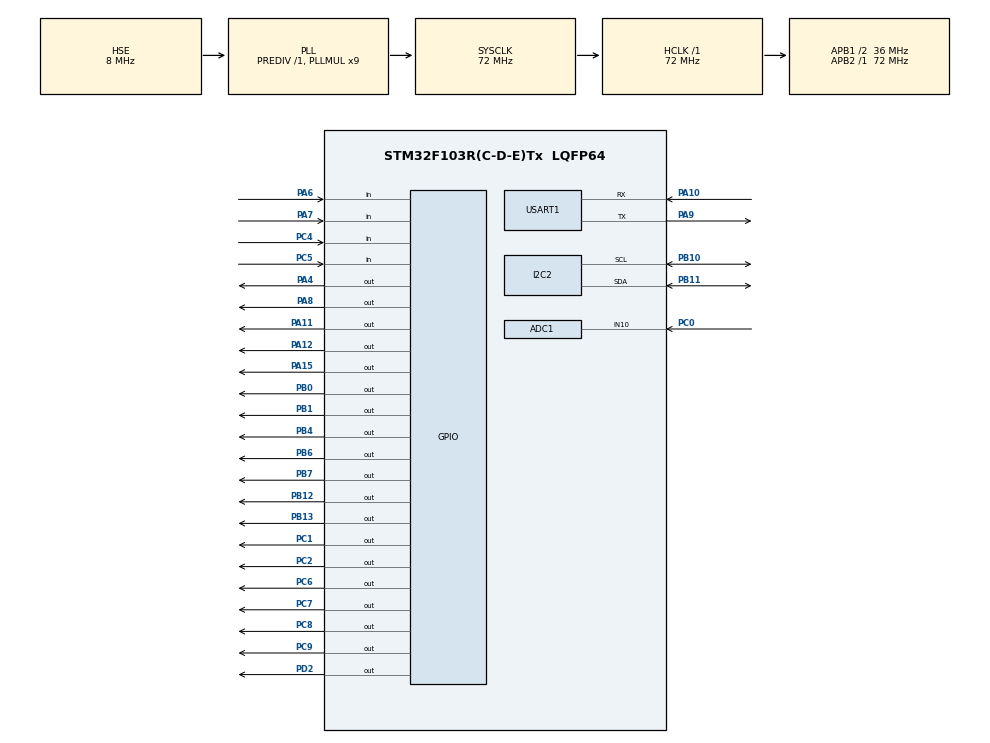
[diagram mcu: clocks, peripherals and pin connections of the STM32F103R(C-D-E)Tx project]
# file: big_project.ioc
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ADC1.Channel-3\#ChannelRegularConversion=ADC_CHANNEL_10
ADC1.ContinuousConvMode=ENABLE
ADC1.NbrOfConversionFlag=1
ADC1.Rank-3\#ChannelRegularConversion=1
ADC1.SamplingTime-3\#ChannelRegularConversion=ADC_SAMPLETIME_1CYCLE_5
ADC1.master=1
Mcu.Family=STM32F1
Mcu.Name=STM32F103R(C-D-E)Tx
Mcu.Package=LQFP64
NVIC.PriorityGroup=NVIC_PRIORITYGROUP_4
NVIC.TIM2_IRQn=true\:0\:0\:false\:false\:true\:true
NVIC.USART1_IRQn=true\:0\:0\:false\:false\:true\:true
PA10.Mode=Asynchronous
PA10.Signal=USART1_RX
PA11.Signal=GPIO_Output
PA12.Signal=GPIO_Output
PA15.Signal=GPIO_Output
PA4.Signal=GPIO_Output
PA6.Signal=GPIO_Input
PA7.Signal=GPIO_Input
PA8.Signal=GPIO_Output
PA9.Mode=Asynchronous
PA9.Signal=USART1_TX
PB0.Signal=GPIO_Output
PB1.Signal=GPIO_Output
PB10.Mode=I2C
PB10.Signal=I2C2_SCL
PB11.Mode=I2C
PB11.Signal=I2C2_SDA
PB12.Signal=GPIO_Output
PB13.Signal=GPIO_Output
PB4.Signal=GPIO_Output
PB6.Signal=GPIO_Output
PB7.Signal=GPIO_Output
PC0.Signal=ADCx_IN10
PC1.Signal=GPIO_Output
PC2.Signal=GPIO_Output
PC4.Signal=GPIO_Input
PC5.Signal=GPIO_Input
PC6.Signal=GPIO_Output
PC7.Signal=GPIO_Output
PC8.Signal=GPIO_Output
PC9.Signal=GPIO_Output
PD0-OSC_IN.Mode=HSE-External-Oscillator
PD0-OSC_IN.Signal=RCC_OSC_IN
PD1-OSC_OUT.Mode=HSE-External-Oscillator
PD1-OSC_OUT.Signal=RCC_OSC_OUT
PD2.Signal=GPIO_Output
ProjectManager.HeapSize=0x200
ProjectManager.StackSize=0x400
ProjectManager.TargetToolchain=MDK-ARM V5
RCC.ADCPresc=RCC_ADCPCLK2_DIV6
RCC.AHBFreq_Value=72000000
RCC.APB1CLKDivider=RCC_HCLK_DIV2
RCC.APB1Freq_Value=36000000
RCC.APB1TimFreq_Value=72000000
RCC.APB2Freq_Value=72000000
RCC.APB2TimFreq_Value=72000000
RCC.HCLKFreq_Value=72000000
RCC.PLLMUL=RCC_PLL_MUL9
RCC.PLLSourceVirtual=RCC_PLLSOURCE_HSE
RCC.SYSCLKFreq_VALUE=72000000
RCC.SYSCLKSource=RCC_SYSCLKSOURCE_PLLCLK
RCC.USBFreq_Value=72000000
SH.ADCx_IN10.0=ADC1_IN10,IN10
TIM2.AutoReloadPreload=TIM_AUTORELOAD_PRELOAD_ENABLE
TIM2.Period=10000
TIM2.Prescaler=7199
USART1.VirtualMode=VM_ASYNC
VP_SYS_VS_ND.Mode=No_Debug
VP_TIM2_VS_ClockSourceINT.Mode=Internal
board=custom

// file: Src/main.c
/* USER CODE BEGIN Header */
/**
  ******************************************************************************
  * @file           : main.c
  * @brief          : Main program body
  ******************************************************************************
  ** This notice applies to any and all portions of this file
  * that are not between comment pairs USER CODE BEGIN and
  * USER CODE END. Other portions of this file, whether
  * inserted by the user or by software development tools
  * are owned by their respective copyright owners.
  *
  * COPYRIGHT(c) 2019 STMicroelectronics
  *
  * Redistribution and use in source and binary forms, with or without modification,
  * are permitted provided that the following conditions are met:
  *   1. Redistributions of source code must retain the above copyright notice,
  *      this list of conditions and the following disclaimer.
  *   2. Redistributions in binary form must reproduce the above copyright notice,
  *      this list of conditions and the following disclaimer in the documentation
  *      and/or other materials provided with the distribution.
  *   3. Neither the name of STMicroelectronics nor the names of its contributors
  *      may be used to endorse or promote products derived from this software
  *      without specific prior written permission.
  *
  * THIS SOFTWARE IS PROVIDED BY THE COPYRIGHT HOLDERS AND CONTRIBUTORS "AS IS"
  * AND ANY EXPRESS OR IMPLIED WARRANTIES, INCLUDING, BUT NOT LIMITED TO, THE
  * IMPLIED WARRANTIES OF MERCHANTABILITY AND FITNESS FOR A PARTICULAR PURPOSE ARE
  * DISCLAIMED. IN NO EVENT SHALL THE COPYRIGHT HOLDER OR CONTRIBUTORS BE LIABLE
  * FOR ANY DIRECT, INDIRECT, INCIDENTAL, SPECIAL, EXEMPLARY, OR CONSEQUENTIAL
  * DAMAGES (INCLUDING, BUT NOT LIMITED TO, PROCUREMENT OF SUBSTITUTE GOODS OR
  * SERVICES; LOSS OF USE, DATA, OR PROFITS; OR BUSINESS INTERRUPTION) HOWEVER
  * CAUSED AND ON ANY THEORY OF LIABILITY, WHETHER IN CONTRACT, STRICT LIABILITY,
  * OR TORT (INCLUDING NEGLIGENCE OR OTHERWISE) ARISING IN ANY WAY OUT OF THE USE
  * OF THIS SOFTWARE, EVEN IF ADVISED OF THE POSSIBILITY OF SUCH DAMAGE.
  *
  ******************************************************************************
  */
/* USER CODE END Header */

#include "main.h"

/* USER CODE BEGIN Includes */
#include "string.h"
#include "math.h"
/* USER CODE END Includes */

ADC_HandleTypeDef hadc1;

I2C_HandleTypeDef hi2c2;

TIM_HandleTypeDef htim2;

UART_HandleTypeDef huart1;

/* USER CODE BEGIN PV */
void key_handle(int key);
/* USER CODE END PV */

void SystemClock_Config(void);
static void MX_GPIO_Init(void);
static void MX_USART1_UART_Init(void);
static void MX_TIM2_Init(void);
static void MX_I2C2_Init(void);
static void MX_ADC1_Init(void);

/* USER CODE BEGIN 0 */
int Tick_ms = 0;
int temp_test2 = 0;
 //设置温度 报警的上下限

int set_para2[4]= {60,20,80,10};
int set_para[4] = {60,20,80,10};  //里面分别是 温度上限，温度下限，报警上限，报警下限。
int get_key[4]={0,0,0,0}; // 用来放按下的有效键
int value_key[] = {12,13,14,15};// 设置键为 温度上限，温度下限 报警上限 报警下限
int delay_time10s=0; // 超过10s没有按键 默认取消操作
int setting = 0;  // 判断是否在设置
int view_para = 0; // 查看参数
struct GPIO_PACK{
		GPIO_TypeDef * port;
		uint16_t pin;
	};
	struct GPIO_PACK segs[8]= {
	{GPIOA,GPIO_PIN_15},
	{GPIOA,GPIO_PIN_11},
	{GPIOC,GPIO_PIN_9},
	{GPIOC,GPIO_PIN_7},
	{GPIOC,GPIO_PIN_8},
	{GPIOA,GPIO_PIN_12},
	{GPIOA,GPIO_PIN_8},
	{GPIOC,GPIO_PIN_6},
	}	;
	struct GPIO_PACK bits[4]={
	{GPIOD,GPIO_PIN_2},
	{GPIOB,GPIO_PIN_4},
	{GPIOB,GPIO_PIN_6},
	{GPIOB,GPIO_PIN_7},

	};
	struct GPIO_PACK led_array[8]=
{
	{GPIOA,GPIO_PIN_4},
	{GPIOA,GPIO_PIN_3},
	{GPIOA,GPIO_PIN_2},
	{GPIOA,GPIO_PIN_1},
	{GPIOA,GPIO_PIN_0},
	{GPIOC,GPIO_PIN_3},
	{GPIOC,GPIO_PIN_2},
	{GPIOC,GPIO_PIN_1},
};
uint8_t shuzu[]={
	0xc0,0xf9,0xa4,0xb0,0x99,0x92,0x82,
	0xf8,0x80,0x90,0xbf
};
uint8_t shuzu2[] = {
	0x40,0x79,0x24,0x30,0x19,0x12,0x2,
	0x78,0x0,0x10
};
void delay1ms (unsigned int a){ // 1ms????(12MHz 10??51??????)
	unsigned int i;
	while( a-- != 0){
		for(i = 0; i < 600; i++);
	}
}
void DisplayOnebit(uint8_t digtal,uint8_t bit){
		uint8_t i;
		for(i=0;i<8;i++){
			HAL_GPIO_WritePin(segs[i].port,segs[i].pin,(GPIO_PinState)(shuzu[digtal]&(0x01<<i)));
		}
		for(i=0;i<4;i++){
			HAL_GPIO_WritePin(bits[i].port,bits[i].pin,(GPIO_PinState)(i!=bit));
		}
		delay1ms(6);
}
void DisplayOnebit2(uint8_t digtal,uint8_t bit){
		uint8_t i;
		for(i=0;i<8;i++){
			HAL_GPIO_WritePin(segs[i].port,segs[i].pin,(GPIO_PinState)(shuzu2[digtal]&(0x01<<i)));
		}
		for(i=0;i<4;i++){
			HAL_GPIO_WritePin(bits[i].port,bits[i].pin,(GPIO_PinState)(i!=bit));
		}
		//HAL_Delay(2);
		delay1ms(6);
}

void DisplayDigtal(uint16_t digtal){

	DisplayOnebit(digtal%10,0);
	HAL_Delay(5);
	if (digtal>=10){
	DisplayOnebit(digtal/10%10,1);
	HAL_Delay(5);
	if (digtal>=100){
	DisplayOnebit(digtal/100%10,2);
	HAL_Delay(5);
	if (digtal>=1000){
	DisplayOnebit(digtal/1000%10,3);
	HAL_Delay(5);

				}
			}
		}
}
struct GPIO_PACK lie[4]={
   {GPIOB,GPIO_PIN_0},
   {GPIOB,GPIO_PIN_1},
   {GPIOB,GPIO_PIN_13},
   {GPIOB,GPIO_PIN_12}
};
struct GPIO_PACK hang[4]={
   {GPIOA,GPIO_PIN_6},
   {GPIOA,GPIO_PIN_7},
   {GPIOC,GPIO_PIN_4},
   {GPIOC,GPIO_PIN_5}
};
void Displaykeying()
	{
		uint8_t i,j,s;uint8_t k=1;volatile int key =0;
		for(i=0;i<4;i++)
	{	 HAL_GPIO_WritePin(lie[i].port,lie[i].pin,GPIO_PIN_RESET);
		for(s=0;s<4;s++){
		if(i!=s)
			HAL_GPIO_WritePin(lie[s].port,lie[s].pin,GPIO_PIN_SET);}
		for(j=0;j<4;j++)
	{	k=HAL_GPIO_ReadPin(hang[j].port,hang[j].pin);
		if(k==0)
			HAL_Delay(5);
			if(k==0)
			switch(j)
			{
				case 0:key=j+1+i;break;
				case 1:key=j+4+i;break;
				case 2:key=j+7+i;break;
				case 3:key=j+10+i;break;
			}
		}
	}
	if (key!=0)
		key_handle(key);
	else
		view_para = 0;
}
void key_handle(int key)  // 此处需要进行对 key 进行判断并做相应的处理
{
for(int j =0;j<4;j++)
	{
		if (value_key[j]==key)
		{
		get_key[0]=key;
		delay_time10s=0;
			setting = 1;
		}
	}
	if(get_key[0]!=0 & key == 11) // 设置负数
	{
		delay_time10s=0;
		setting = 1;
		get_key[1]=1;
	}
	if (get_key[0]!=0 & key<=10 & key!=0)
	{

		int key_time_delay = delay_time10s;
		delay_time10s=0;  // 重新计时  10s
		setting = 1;
	 if (get_key[2]!=0)
	 {
		if(key_time_delay<=2 & key==get_key[2]) //由于有按键抖动，按一下可能获取到了多个值，用delay可能会解决不掉
																						//判断上一次和这次的输入时间差  如果小于2秒而且两次的值一样 就认为是抖动造成的
		get_key[3] = 0;
		else
			get_key[3] = key;
	 }else if(get_key[2]==0)
	 {
	 get_key[2] = key;
	 }

	}

	if(get_key[0]!=0 & get_key[2]!=0 & key==16)  //确认保存键
	{

		handle_get_key(get_key);
		setpara_towrite();
		for (int i =0;i<4;i++)
				get_key [i]= 0;
		setting = 0;

	}
	if(get_key[0]==0 & key == 16) // 查看报警上下限
	{
		view_para=1;
	}else
	view_para = 0;

}

#define ADDR_AT24C02_Write 0xA0
#define ADDR_AT24C02_Read 0xA1
#define BufferSize 0x100
uint16_t i;
uint8_t  AT24c02_flag;//
uint8_t params[12]="0";  //用来写入和读出
uint8_t trans_str[2]="0";  // 用来把整形转换为字符型
//int set_para[4] = {60,20,80,10};  //里面分别是 温度上限，温度下限，报警上限，报警下限。
//int value_key[] = {12,13,14,15};// 设置键为 温度上限，温度下限 报警上限 报警下限

void Int2Str(uint8_t* str, int intnum)   //将无符号整形整数intnum 转换成字符 str
{
    int i, Div = 1000000000, j = 0, Status = 0;
    for (i = 0; i < 10; i++)
    {
        str[j++] = (intnum / Div) + '0';
        intnum = intnum % Div;//?????
        Div /= 10;
        if ((str[j-1] == '0') & (Status == 0))
            j = 0;
        else
            Status++;
    }
}
void handle_get_key(int *handle_key)  // 当有值被改变后 对参数进行修改
{
	int set_value;
	if (handle_key[3] ==0 ) // 只输入了一位数
		set_value =handle_key[2];
	else
		set_value = handle_key[2]*10+handle_key[3]%10; // 10代表的是0 而且 所以用了取余省去了很多的判断
	if (handle_key[1]==1)
		set_value = ~set_value+1; // 取 相反数
	for(int j=0;j<4;j++)  //匹配是哪个功能
	{
 if (handle_key[0]== value_key[j])
	set_para[j]=set_value;
}

}
void warning(int temp_warn)
{
if (temp_warn<=set_para[3]) // 温度低于警报下限
{
HAL_GPIO_WritePin(GPIOC,GPIO_PIN_12,1); //响铃式报警
HAL_GPIO_WritePin(GPIOC,GPIO_PIN_1,1);
delay1ms(2);

}
else if(temp_warn>=set_para[2])//温度高于警报上限
{
HAL_GPIO_WritePin(GPIOC,GPIO_PIN_12,1); //响铃式报警
HAL_GPIO_WritePin(GPIOC,GPIO_PIN_1,1);
delay1ms(3);

}
else
{
	HAL_GPIO_WritePin(GPIOC,GPIO_PIN_1,0);
	HAL_GPIO_WritePin(GPIOC,GPIO_PIN_12,0);
}
}

void setpara_towrite() // 把参数写入 由于需要判断正负数 所以在 数前面添加0或者1来区分

{

//	uint8_t params3[12]="060020080010"; 60 20 80 10 四个数都是整数前面都加0 连在一块写入
//	uint8_t params2[4]="0010";
		//HAL_UART_Transmit_IT(&huart1,paramss,12);
	uint8_t params3[12]="";
	uint8_t params2[4]="";
	int value =0;
 for (int i=0;i<4;i++)
	{

		if (set_para[i]>=0)
		{	strncat(params3,"0",1);
			value = set_para[i];
		}
		else
		{strncat(params3,"1",1);
			value = ~set_para[i]+1;
		}
		Int2Str(trans_str,value);

		if(value>=0 & value<10)
		{	strncat(params3,"0",1);
			strncat(params3,trans_str,1);
		}else
		strncat(params3,trans_str,2);

	}
	for(int j=8;j<12;j++)
{

	params2[j-8]=params3[j];

}

	HAL_I2C_Mem_Write(&hi2c2, ADDR_AT24C02_Write, 0, I2C_MEMADD_SIZE_8BIT,params3,8, 10000);
	HAL_Delay(5);
	HAL_I2C_Mem_Write(&hi2c2, ADDR_AT24C02_Write, 8, I2C_MEMADD_SIZE_8BIT,params2,8, 10000);
	HAL_Delay(5);

}
void handle_readpara()  // 从EEprom中读出来的值进行处理 判断正负以及分开
{
	int num =0;
	int abc ;
for(int i=0;i<12;i++)
	{
		if((i+1)%3 == 1)
		{
			num = (params[i+1]-48)*10+params[i+2]-48;
			abc = params[i]-48;
			if (abc==1)
				num = ~num+1;  // 为1 可以判断为负数
			set_para[i/3]=num;

		}

	}
}
void Display_tube(int temp_test)  // 控制数码管的显示
{
 int ture_num ;
if (view_para!=1)
	{
		if(setting == 0 )
	{
		if(temp_test<0)
			ture_num = ~temp_test+1;
		else
			ture_num = temp_test;

	DisplayOnebit(ture_num%10,0);
	DisplayOnebit2(ture_num/10%10,1);
	if(temp_test>=100)
	{
		DisplayOnebit(ture_num/100,2);
		if(temp_test<0)
		DisplayOnebit(10,3);
		}else if(temp_test<0)
		DisplayOnebit(10,2);  //负数显示一个横杠
	}
	if(setting == 1)
	{
	DisplayOnebit(get_key[0]%10,3);
	DisplayOnebit(9-delay_time10s,2);
	DisplayOnebit(get_key[2]%10,1);
	DisplayOnebit(get_key[3]%10,0);
	}
	}else if(view_para==1) //查看上下限参数
		{
		if (set_para[2]<0)
		{DisplayOnebit2((~set_para[2]+1)%10,2);
			DisplayOnebit((~set_para[2]+1)/10,3);}
			else
			{DisplayOnebit(set_para[2]%10,2);
				DisplayOnebit(set_para[2]/10,3);}
			// 上面是显示上限 下面是下限
			if (set_para[3]<0)
				{DisplayOnebit2((~set_para[3]+1)%10,0);
			DisplayOnebit((~set_para[3]+1)/10,1);}
			else
			{DisplayOnebit(set_para[3]%10,0);
				DisplayOnebit(set_para[3]/10,1);}
		}

}

float array_Temp[] = {  //使用查表法  温度表
-40,-30,-20,-10,-5,-3,-1,0,
2,4,6,8,10,13,15,18,
20,22,24,25,26,27,28,29,
30,31,32,33,34,35,36,37,38,
39,40,42,45,48,52,60,65,
70,75,80,85,90,95,100,105,

};
float array_Resis[] = {   //使用查表法  阻值表
201,116,70.03,43.35,34.48,31.52,28.85,27.62,
25.32,23.23,21.34,19.63,18.07,15.98,14.47,13.09,
12.11,11.21,10.39,10.00,9.631,9.277,8.938,8.613,
8.302,8.004,7.718,7.444,7.180,6.928,6.683,6.654,6.230,
6.016,5.810,5.423,4.897,4.429,3.883,3.001,2.582,
2.223,1.921,1.667,1.451,1.268,1.112,0.977,0,8262,

};
float search_temp(float rsis)  //二分查找法
{
int start=0,end=sizeof(array_Temp);
	int j;
while(1)
{
j = (end + start)/2;
if (rsis > array_Resis[j])
{

	end = j-1;
}
else if (rsis == array_Resis[j])
	break;
else
	start = j+1;
if (end - start <0)
	break;
}

 if (start-end ==1)
{
	float R = (array_Temp[start]-array_Temp[end])/(array_Resis[start]-array_Resis[end])*(rsis-array_Resis[end])+array_Temp[end];
	//DisplayDigtal(end);
	return R;
}else
	return array_Temp[j];

}
float ADC1temp(void)  // AD采样值 计算阻值 并获取温度
{
	 uint16_t ADC1_Value;
  	 float  Rt,t;
	float false_temp,ture_temp;
	 HAL_ADC_Start(&hadc1);
   	HAL_ADC_PollForConversion(&hadc1, 50);
 	if(HAL_IS_BIT_SET(HAL_ADC_GetState(&hadc1), HAL_ADC_STATE_REG_EOC))
  	 {
	   ADC1_Value = HAL_ADC_GetValue(&hadc1);
   	 Rt=(10000*ADC1_Value)/ (4096-ADC1_Value); // 热敏电阻值
			t=(1/(log((Rt/10000))/3380+1/(273.15+25))-273.15);  //t=1/(ln(Rt/R0)/B+1/T0)-273.15
		ture_temp = t*10; // 计算出来的
		false_temp = ((search_temp(Rt))*10);//使用查表法的温度值

		return ture_temp;
 	 }
 }

/* USER CODE END 0 */

int main(void)
{

  /* MCU Configuration--------------------------------------------------------*/

  /* Reset of all peripherals, Initializes the Flash interface and the Systick. */
  HAL_Init();

  /* USER CODE BEGIN Init */
	// HAL_GPIO_TogglePin(GPIOA,GPIO_PIN_1);
//	HAL_GPIO_TogglePin(GPIOA,GPIO_PIN_2);
  /* USER CODE END Init */

  /* Configure the system clock */
  SystemClock_Config();

  /* Initialize all configured peripherals */
  MX_GPIO_Init();
  MX_USART1_UART_Init();
  MX_TIM2_Init();
  MX_I2C2_Init();
  MX_ADC1_Init();
  /* USER CODE BEGIN 2 */

	//HAL_TIM_Base_Start_IT(&htim2); // 开启定时器2的中断

	if(HAL_I2C_Mem_Read(&hi2c2, ADDR_AT24C02_Read,0,I2C_MEMADD_SIZE_8BIT,params,12,1000) == HAL_OK)
	{

		HAL_UART_Transmit_IT(&huart1,params,12);
		handle_readpara(); //处理读出的数值
	}
	int get_temp =ADC1temp();;

  /* USER CODE END 2 */

  /* Infinite loop */
  while (1)
  {

    /* USER CODE BEGIN 3 */
		//Displaykeying();
		if(temp_test2==0)
			get_temp = ADC1temp();// 定时 获取阻值
		warning(get_temp/10); // 对放入的值 判断警报
		Displaykeying();
		Display_tube(get_temp); // 放入的是 get——temp的时候是 温度 放入temp——test2 测试是用来测试

  }

  /* USER CODE END 3 */
}

void SystemClock_Config(void)
{
  RCC_OscInitTypeDef RCC_OscInitStruct = {0};
  RCC_ClkInitTypeDef RCC_ClkInitStruct = {0};
  RCC_PeriphCLKInitTypeDef PeriphClkInit = {0};

  /**Initializes the CPU, AHB and APB busses clocks
  */
  RCC_OscInitStruct.OscillatorType = RCC_OSCILLATORTYPE_HSE;
  RCC_OscInitStruct.HSEState = RCC_HSE_ON;
  RCC_OscInitStruct.HSEPredivValue = RCC_HSE_PREDIV_DIV1;
  RCC_OscInitStruct.HSIState = RCC_HSI_ON;
  RCC_OscInitStruct.PLL.PLLState = RCC_PLL_ON;
  RCC_OscInitStruct.PLL.PLLSource = RCC_PLLSOURCE_HSE;
  RCC_OscInitStruct.PLL.PLLMUL = RCC_PLL_MUL9;
  if (HAL_RCC_OscConfig(&RCC_OscInitStruct) != HAL_OK)
  {
    Error_Handler();
  }
  /**Initializes the CPU, AHB and APB busses clocks
  */
  RCC_ClkInitStruct.ClockType = RCC_CLOCKTYPE_HCLK|RCC_CLOCKTYPE_SYSCLK
                              |RCC_CLOCKTYPE_PCLK1|RCC_CLOCKTYPE_PCLK2;
  RCC_ClkInitStruct.SYSCLKSource = RCC_SYSCLKSOURCE_PLLCLK;
  RCC_ClkInitStruct.AHBCLKDivider = RCC_SYSCLK_DIV1;
  RCC_ClkInitStruct.APB1CLKDivider = RCC_HCLK_DIV2;
  RCC_ClkInitStruct.APB2CLKDivider = RCC_HCLK_DIV1;

  if (HAL_RCC_ClockConfig(&RCC_ClkInitStruct, FLASH_LATENCY_2) != HAL_OK)
  {
    Error_Handler();
  }
  PeriphClkInit.PeriphClockSelection = RCC_PERIPHCLK_ADC;
  PeriphClkInit.AdcClockSelection = RCC_ADCPCLK2_DIV6;
  if (HAL_RCCEx_PeriphCLKConfig(&PeriphClkInit) != HAL_OK)
  {
    Error_Handler();
  }
}

static void MX_ADC1_Init(void)
{

  ADC_ChannelConfTypeDef sConfig = {0};

  /**Common config
  */
  hadc1.Instance = ADC1;
  hadc1.Init.ScanConvMode = ADC_SCAN_DISABLE;
  hadc1.Init.ContinuousConvMode = ENABLE;
  hadc1.Init.DiscontinuousConvMode = DISABLE;
  hadc1.Init.ExternalTrigConv = ADC_SOFTWARE_START;
  hadc1.Init.DataAlign = ADC_DATAALIGN_RIGHT;
  hadc1.Init.NbrOfConversion = 1;
  if (HAL_ADC_Init(&hadc1) != HAL_OK)
  {
    Error_Handler();
  }
  /**Configure Regular Channel
  */
  sConfig.Channel = ADC_CHANNEL_10;
  sConfig.Rank = ADC_REGULAR_RANK_1;
  sConfig.SamplingTime = ADC_SAMPLETIME_1CYCLE_5;
  if (HAL_ADC_ConfigChannel(&hadc1, &sConfig) != HAL_OK)
  {
    Error_Handler();
  }

}

static void MX_I2C2_Init(void)
{

  hi2c2.Instance = I2C2;
  hi2c2.Init.ClockSpeed = 100000;
  hi2c2.Init.DutyCycle = I2C_DUTYCYCLE_2;
  hi2c2.Init.OwnAddress1 = 0;
  hi2c2.Init.AddressingMode = I2C_ADDRESSINGMODE_7BIT;
  hi2c2.Init.DualAddressMode = I2C_DUALADDRESS_DISABLE;
  hi2c2.Init.OwnAddress2 = 0;
  hi2c2.Init.GeneralCallMode = I2C_GENERALCALL_DISABLE;
  hi2c2.Init.NoStretchMode = I2C_NOSTRETCH_DISABLE;
  if (HAL_I2C_Init(&hi2c2) != HAL_OK)
  {
    Error_Handler();
  }

}

static void MX_TIM2_Init(void)
{

  TIM_ClockConfigTypeDef sClockSourceConfig = {0};
  TIM_MasterConfigTypeDef sMasterConfig = {0};

  htim2.Instance = TIM2;
  htim2.Init.Prescaler = 7199;
  htim2.Init.CounterMode = TIM_COUNTERMODE_UP;
  htim2.Init.Period = 10000;
  htim2.Init.ClockDivision = TIM_CLOCKDIVISION_DIV1;
  htim2.Init.AutoReloadPreload = TIM_AUTORELOAD_PRELOAD_ENABLE;
  if (HAL_TIM_Base_Init(&htim2) != HAL_OK)
  {
    Error_Handler();
  }
  sClockSourceConfig.ClockSource = TIM_CLOCKSOURCE_INTERNAL;
  if (HAL_TIM_ConfigClockSource(&htim2, &sClockSourceConfig) != HAL_OK)
  {
    Error_Handler();
  }
  sMasterConfig.MasterOutputTrigger = TIM_TRGO_RESET;
  sMasterConfig.MasterSlaveMode = TIM_MASTERSLAVEMODE_DISABLE;
  if (HAL_TIMEx_MasterConfigSynchronization(&htim2, &sMasterConfig) != HAL_OK)
  {
    Error_Handler();
  }

}

static void MX_USART1_UART_Init(void)
{

  huart1.Instance = USART1;
  huart1.Init.BaudRate = 115200;
  huart1.Init.WordLength = UART_WORDLENGTH_8B;
  huart1.Init.StopBits = UART_STOPBITS_1;
  huart1.Init.Parity = UART_PARITY_NONE;
  huart1.Init.Mode = UART_MODE_TX_RX;
  huart1.Init.HwFlowCtl = UART_HWCONTROL_NONE;
  huart1.Init.OverSampling = UART_OVERSAMPLING_16;
  if (HAL_UART_Init(&huart1) != HAL_OK)
  {
    Error_Handler();
  }

}

static void MX_GPIO_Init(void)
{
  GPIO_InitTypeDef GPIO_InitStruct = {0};

  /* GPIO Ports Clock Enable */
  __HAL_RCC_GPIOD_CLK_ENABLE();
  __HAL_RCC_GPIOC_CLK_ENABLE();
  __HAL_RCC_GPIOA_CLK_ENABLE();
  __HAL_RCC_GPIOB_CLK_ENABLE();

  /*Configure GPIO pin Output Level */
  HAL_GPIO_WritePin(GPIOC, GPIO_PIN_1|GPIO_PIN_12|GPIO_PIN_6|GPIO_PIN_7
                          |GPIO_PIN_8|GPIO_PIN_9, GPIO_PIN_RESET);

  /*Configure GPIO pin Output Level */
  HAL_GPIO_WritePin(GPIOA, GPIO_PIN_4|GPIO_PIN_8|GPIO_PIN_11|GPIO_PIN_12
                          |GPIO_PIN_15, GPIO_PIN_RESET);

  /*Configure GPIO pin Output Level */
  HAL_GPIO_WritePin(GPIOB, GPIO_PIN_0|GPIO_PIN_1|GPIO_PIN_12|GPIO_PIN_13
                          |GPIO_PIN_4|GPIO_PIN_6|GPIO_PIN_7, GPIO_PIN_RESET);

  /*Configure GPIO pin Output Level */
  HAL_GPIO_WritePin(GPIOD, GPIO_PIN_2, GPIO_PIN_RESET);

  /*Configure GPIO pins : PC1 PC2 PC6 PC7
                           PC8 PC9 */
  GPIO_InitStruct.Pin = GPIO_PIN_1|GPIO_PIN_12|GPIO_PIN_6|GPIO_PIN_7
                          |GPIO_PIN_8|GPIO_PIN_9;
  GPIO_InitStruct.Mode = GPIO_MODE_OUTPUT_PP;
  GPIO_InitStruct.Pull = GPIO_NOPULL;
  GPIO_InitStruct.Speed = GPIO_SPEED_FREQ_LOW;
  HAL_GPIO_Init(GPIOC, &GPIO_InitStruct);

  /*Configure GPIO pins : PA4 PA8 PA11 PA12
                           PA15 */
  GPIO_InitStruct.Pin = GPIO_PIN_4|GPIO_PIN_8|GPIO_PIN_11|GPIO_PIN_12
                          |GPIO_PIN_15;
  GPIO_InitStruct.Mode = GPIO_MODE_OUTPUT_PP;
  GPIO_InitStruct.Pull = GPIO_NOPULL;
  GPIO_InitStruct.Speed = GPIO_SPEED_FREQ_LOW;
  HAL_GPIO_Init(GPIOA, &GPIO_InitStruct);

  /*Configure GPIO pins : PA6 PA7 */
  GPIO_InitStruct.Pin = GPIO_PIN_6|GPIO_PIN_7;
  GPIO_InitStruct.Mode = GPIO_MODE_INPUT;
  GPIO_InitStruct.Pull = GPIO_NOPULL;
  HAL_GPIO_Init(GPIOA, &GPIO_InitStruct);

  /*Configure GPIO pins : PC4 PC5 */
  GPIO_InitStruct.Pin = GPIO_PIN_4|GPIO_PIN_5;
  GPIO_InitStruct.Mode = GPIO_MODE_INPUT;
  GPIO_InitStruct.Pull = GPIO_NOPULL;
  HAL_GPIO_Init(GPIOC, &GPIO_InitStruct);

  /*Configure GPIO pins : PB0 PB1 PB12 PB13
                           PB4 PB6 PB7 */
  GPIO_InitStruct.Pin = GPIO_PIN_0|GPIO_PIN_1|GPIO_PIN_12|GPIO_PIN_13
                          |GPIO_PIN_4|GPIO_PIN_6|GPIO_PIN_7;
  GPIO_InitStruct.Mode = GPIO_MODE_OUTPUT_PP;
  GPIO_InitStruct.Pull = GPIO_NOPULL;
  GPIO_InitStruct.Speed = GPIO_SPEED_FREQ_LOW;
  HAL_GPIO_Init(GPIOB, &GPIO_InitStruct);

  /*Configure GPIO pin : PD2 */
  GPIO_InitStruct.Pin = GPIO_PIN_2;
  GPIO_InitStruct.Mode = GPIO_MODE_OUTPUT_PP;
  GPIO_InitStruct.Pull = GPIO_NOPULL;
  GPIO_InitStruct.Speed = GPIO_SPEED_FREQ_LOW;
  HAL_GPIO_Init(GPIOD, &GPIO_InitStruct);

}

/* USER CODE BEGIN 4 */  //systick
void HAL_SYSTICK_Callback(void)
{
		Tick_ms++;
		if(Tick_ms%1000==0)
	{

		delay_time10s++;
		Tick_ms = 0;
		temp_test2 = temp_test2+9;
		if (temp_test2>99)
			temp_test2 = -9;
		if (delay_time10s >=10 )
			{
			for (int i =0;i<4;i++)
				get_key [i]= 0;
				delay_time10s =0;
				setting=0;
			}
		}
		if(setting==1 & Tick_ms%250==0)
			HAL_GPIO_TogglePin(GPIOA,GPIO_PIN_4);
		if(setting==0)
			HAL_GPIO_WritePin(GPIOA,GPIO_PIN_4,1);
}

//void HAL_TIM_PeriodElapsedCallback(TIM_HandleTypeDef *htim)  // 定时器中断
//{
//    if (htim->Instance == htim2.Instance)
//    {
//        	/* Toggle LED */
//		HAL_GPIO_TogglePin(GPIOA,GPIO_PIN_4);
//		delay_time10s++;
//		Tick_ms = 0;
//		temp_test2 = temp_test2+9;// temp_test 可以用来测试上下限 也可以用来定时 获取温度值
//		if (temp_test2>99)
//			temp_test2 = -18;
//		if (delay_time10s >=10 )
//			{
//			for (int i =0;i<4;i++)
//				get_key [i]= 0;
//				delay_time10s =0;
//				setting=0;
//			}
//			if(delay_time10s >0)
//				HAL_GPIO_TogglePin(GPIOA,GPIO_PIN_4);
//
//    }
//}

/* USER CODE END 4 */

void Error_Handler(void)
{
}

/************************ (C) COPYRIGHT STMicroelectronics *****END OF FILE****/
